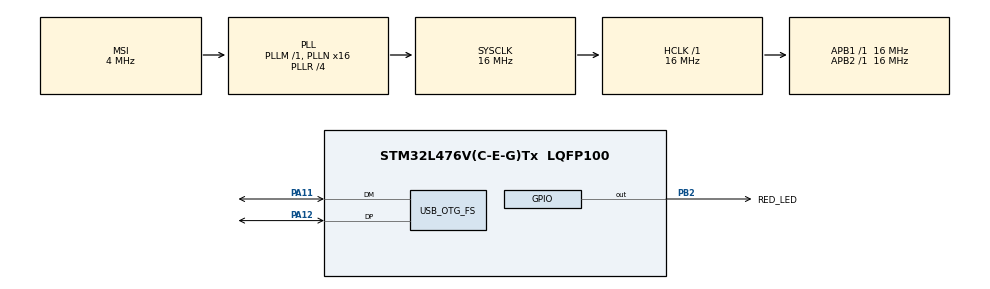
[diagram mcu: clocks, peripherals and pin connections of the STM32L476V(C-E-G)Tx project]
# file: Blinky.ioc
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FREERTOS.Tasks01=defaultTask,24,128,StartDefaultTask,Default,NULL,Dynamic,NULL,NULL
FREERTOS.configUSE_TICKLESS_IDLE=0
Mcu.Family=STM32L4
Mcu.Name=STM32L476V(C-E-G)Tx
Mcu.Package=LQFP100
NVIC.OTG_FS_IRQn=true\:5\:0\:false\:false\:true\:true\:false\:true
NVIC.PriorityGroup=NVIC_PRIORITYGROUP_4
NVIC.TIM1_UP_TIM16_IRQn=true\:0\:0\:false\:false\:true\:false\:false\:true
NVIC.TimeBase=TIM1_UP_TIM16_IRQn
NVIC.TimeBaseIP=TIM1
PA11.Mode=Device_Only
PA11.Signal=USB_OTG_FS_DM
PA12.Mode=Device_Only
PA12.Signal=USB_OTG_FS_DP
PB2.GPIO_Label=RED_LED
PB2.GPIO_Speed=GPIO_SPEED_FREQ_MEDIUM
PB2.Signal=GPIO_Output
ProjectManager.HeapSize=0x200
ProjectManager.StackSize=0x400
ProjectManager.TargetToolchain=STM32CubeIDE
RCC.ADCFreq_Value=48000000
RCC.AHBFreq_Value=16000000
RCC.APB1Freq_Value=16000000
RCC.APB1TimFreq_Value=16000000
RCC.APB2Freq_Value=16000000
RCC.APB2TimFreq_Value=16000000
RCC.CortexFreq_Value=16000000
RCC.HCLKFreq_Value=16000000
RCC.HSE_VALUE=8000000
RCC.HSI_VALUE=16000000
RCC.LSE_VALUE=32768
RCC.MSI_VALUE=4000000
RCC.PLLN=16
RCC.PLLR=RCC_PLLR_DIV4
RCC.PLLSAI1N=24
RCC.SYSCLKFreq_VALUE=16000000
RCC.SYSCLKSource=RCC_SYSCLKSOURCE_PLLCLK
RCC.USBFreq_Value=48000000
RCC.VCOOutputFreq_Value=64000000
USB_DEVICE.CLASS_NAME_FS=CDC
USB_DEVICE.VirtualMode=Cdc
USB_DEVICE.VirtualModeFS=Cdc_FS
USB_OTG_FS.VirtualMode=Device_Only
VP_FREERTOS_VS_CMSIS_V2.Mode=CMSIS_V2
VP_SYS_VS_tim1.Mode=TIM1
VP_USB_DEVICE_VS_USB_DEVICE_CDC_FS.Mode=CDC_FS
board=custom

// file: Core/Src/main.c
/* USER CODE BEGIN Header */
/**
  ******************************************************************************
  * @file           : main.c
  * @brief          : Main program body
  ******************************************************************************
  * @attention
  *
  * <h2><center>&copy; Copyright (c) 2020 STMicroelectronics.
  * All rights reserved.</center></h2>
  *
  * This software component is licensed by ST under BSD 3-Clause license,
  * the "License"; You may not use this file except in compliance with the
  * License. You may obtain a copy of the License at:
  *                        opensource.org/licenses/BSD-3-Clause
  *
  ******************************************************************************
  */
/* USER CODE END Header */

#include "main.h"
#include "cmsis_os.h"
#include "usb_device.h"

/* USER CODE BEGIN Includes */

#include "usbd_cdc_if.h"
#include "string.h"
#include "stdio.h"

/* USER CODE END Includes */

/* USER CODE BEGIN PD */

#define MY_CDC_BUFFER_LEN 4095

/* USER CODE END PD */

/* Definitions for defaultTask */
osThreadId_t defaultTaskHandle;
const osThreadAttr_t defaultTask_attributes = {
  .name = "defaultTask",
  .priority = (osPriority_t) osPriorityNormal,
  .stack_size = 128 * 4
};

void SystemClock_Config(void);
static void MX_GPIO_Init(void);
void StartDefaultTask(void *argument);

/* USER CODE BEGIN 0 */

static char serialbuffer[MY_CDC_BUFFER_LEN + 1];

/* USER CODE END 0 */

int main(void)
{

  /* MCU Configuration--------------------------------------------------------*/

  /* Reset of all peripherals, Initializes the Flash interface and the Systick. */
  HAL_Init();

  /* USER CODE BEGIN Init */

  serialbuffer[MY_CDC_BUFFER_LEN] = 0;
  serialbuffer[0] = 0;

  /* USER CODE END Init */

  /* Configure the system clock */
  SystemClock_Config();

  /* Initialize all configured peripherals */
  MX_GPIO_Init();

  /* Init scheduler */
  osKernelInitialize();

  /* Create the thread(s) */
  /* creation of defaultTask */
  defaultTaskHandle = osThreadNew(StartDefaultTask, NULL, &defaultTask_attributes);

  /* Start scheduler */
  osKernelStart();

  /* We should never get here as control is now taken by the scheduler */
  /* Infinite loop */
  while (1)
  {

  }
}

void SystemClock_Config(void)
{
  RCC_OscInitTypeDef RCC_OscInitStruct = {0};
  RCC_ClkInitTypeDef RCC_ClkInitStruct = {0};
  RCC_PeriphCLKInitTypeDef PeriphClkInit = {0};

  /** Initializes the CPU, AHB and APB busses clocks
  */
  RCC_OscInitStruct.OscillatorType = RCC_OSCILLATORTYPE_MSI;
  RCC_OscInitStruct.MSIState = RCC_MSI_ON;
  RCC_OscInitStruct.MSICalibrationValue = 0;
  RCC_OscInitStruct.MSIClockRange = RCC_MSIRANGE_6;
  RCC_OscInitStruct.PLL.PLLState = RCC_PLL_ON;
  RCC_OscInitStruct.PLL.PLLSource = RCC_PLLSOURCE_MSI;
  RCC_OscInitStruct.PLL.PLLM = 1;
  RCC_OscInitStruct.PLL.PLLN = 16;
  RCC_OscInitStruct.PLL.PLLP = RCC_PLLP_DIV7;
  RCC_OscInitStruct.PLL.PLLQ = RCC_PLLQ_DIV2;
  RCC_OscInitStruct.PLL.PLLR = RCC_PLLR_DIV4;
  if (HAL_RCC_OscConfig(&RCC_OscInitStruct) != HAL_OK)
  {
    Error_Handler();
  }
  /** Initializes the CPU, AHB and APB busses clocks
  */
  RCC_ClkInitStruct.ClockType = RCC_CLOCKTYPE_HCLK|RCC_CLOCKTYPE_SYSCLK
                              |RCC_CLOCKTYPE_PCLK1|RCC_CLOCKTYPE_PCLK2;
  RCC_ClkInitStruct.SYSCLKSource = RCC_SYSCLKSOURCE_PLLCLK;
  RCC_ClkInitStruct.AHBCLKDivider = RCC_SYSCLK_DIV1;
  RCC_ClkInitStruct.APB1CLKDivider = RCC_HCLK_DIV1;
  RCC_ClkInitStruct.APB2CLKDivider = RCC_HCLK_DIV1;

  if (HAL_RCC_ClockConfig(&RCC_ClkInitStruct, FLASH_LATENCY_0) != HAL_OK)
  {
    Error_Handler();
  }
  PeriphClkInit.PeriphClockSelection = RCC_PERIPHCLK_USB;
  PeriphClkInit.UsbClockSelection = RCC_USBCLKSOURCE_PLLSAI1;
  PeriphClkInit.PLLSAI1.PLLSAI1Source = RCC_PLLSOURCE_MSI;
  PeriphClkInit.PLLSAI1.PLLSAI1M = 1;
  PeriphClkInit.PLLSAI1.PLLSAI1N = 24;
  PeriphClkInit.PLLSAI1.PLLSAI1P = RCC_PLLP_DIV7;
  PeriphClkInit.PLLSAI1.PLLSAI1Q = RCC_PLLQ_DIV2;
  PeriphClkInit.PLLSAI1.PLLSAI1R = RCC_PLLR_DIV2;
  PeriphClkInit.PLLSAI1.PLLSAI1ClockOut = RCC_PLLSAI1_48M2CLK;
  if (HAL_RCCEx_PeriphCLKConfig(&PeriphClkInit) != HAL_OK)
  {
    Error_Handler();
  }
  /** Configure the main internal regulator output voltage
  */
  if (HAL_PWREx_ControlVoltageScaling(PWR_REGULATOR_VOLTAGE_SCALE1) != HAL_OK)
  {
    Error_Handler();
  }
}

static void MX_GPIO_Init(void)
{
  GPIO_InitTypeDef GPIO_InitStruct = {0};

  /* GPIO Ports Clock Enable */
  __HAL_RCC_GPIOB_CLK_ENABLE();
  __HAL_RCC_GPIOA_CLK_ENABLE();

  /*Configure GPIO pin Output Level */
  HAL_GPIO_WritePin(RED_LED_GPIO_Port, RED_LED_Pin, GPIO_PIN_RESET);

  /*Configure GPIO pin : RED_LED_Pin */
  GPIO_InitStruct.Pin = RED_LED_Pin;
  GPIO_InitStruct.Mode = GPIO_MODE_OUTPUT_PP;
  GPIO_InitStruct.Pull = GPIO_NOPULL;
  GPIO_InitStruct.Speed = GPIO_SPEED_FREQ_MEDIUM;
  HAL_GPIO_Init(RED_LED_GPIO_Port, &GPIO_InitStruct);

}

void StartDefaultTask(void *argument)
{
  /* init code for USB_DEVICE */
  MX_USB_DEVICE_Init();
  /* USER CODE BEGIN 5 */
  /* Infinite loop */
  size_t counter = 0;
  for(;;)
  {
    HAL_GPIO_WritePin(RED_LED_GPIO_Port, RED_LED_Pin, GPIO_PIN_SET);
    osDelay(25);
    HAL_GPIO_WritePin(RED_LED_GPIO_Port, RED_LED_Pin, GPIO_PIN_RESET);
    size_t msg_len = snprintf(serialbuffer, MY_CDC_BUFFER_LEN, "Tick %d\r\n", counter);
    CDC_Transmit_FS((uint8_t*)serialbuffer, msg_len);
    counter += 1;
    osDelay(975);
  }
  /* USER CODE END 5 */
}

 /**
  * @brief  Period elapsed callback in non blocking mode
  * @note   This function is called  when TIM1 interrupt took place, inside
  * HAL_TIM_IRQHandler(). It makes a direct call to HAL_IncTick() to increment
  * a global variable "uwTick" used as application time base.
  * @param  htim : TIM handle
  * @retval None
  */
void HAL_TIM_PeriodElapsedCallback(TIM_HandleTypeDef *htim)
{
  if (htim->Instance == TIM1) {
    HAL_IncTick();
  }
}

void Error_Handler(void)
{
}

/************************ (C) COPYRIGHT STMicroelectronics *****END OF FILE****/
